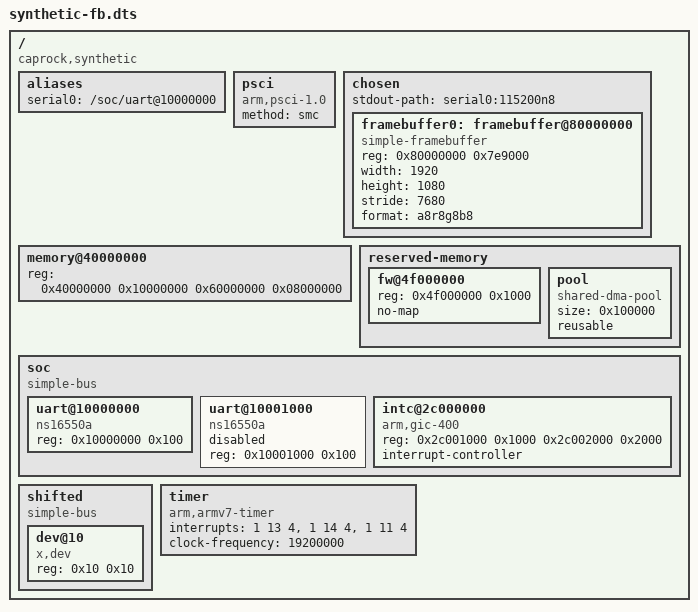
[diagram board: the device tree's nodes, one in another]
/dts-v1/;
/memreserve/ 0x4e000000 0x100000;
/* Hand-written fixture: 32-bit cells, two memory regions, header reservation, simple-framebuffer,
   alias-based stdout-path with options. Regenerate with `dtc -I dts -O dtb`. */
/ {
	#address-cells = <1>;
	#size-cells = <1>;
	compatible = "caprock,synthetic";
	aliases { serial0 = "/soc/uart@10000000"; };
	psci {
		compatible = "arm,psci-1.0", "arm,psci-0.2", "arm,psci";
		method = "smc";
	};
	chosen {
		#address-cells = <1>; #size-cells = <1>; ranges;
		stdout-path = "serial0:115200n8";
		framebuffer0: framebuffer@80000000 {
			compatible = "simple-framebuffer";
			reg = <0x80000000 0x7e9000>;
			width = <1920>;
			height = <1080>;
			stride = <7680>;
			format = "a8r8g8b8";
		};
	};
	memory@40000000 { device_type = "memory"; reg = <0x40000000 0x10000000 0x60000000 0x08000000>; };
	reserved-memory {
		#address-cells = <1>; #size-cells = <1>; ranges;
		fw@4f000000 { reg = <0x4f000000 0x1000>; no-map; };
		pool { size = <0x100000>; compatible = "shared-dma-pool"; reusable; };
	};
	soc {
		compatible = "simple-bus";
		#address-cells = <1>; #size-cells = <1>;
		ranges;
		uart@10000000 { compatible = "ns16550a"; reg = <0x10000000 0x100>; };
		uart@10001000 { compatible = "ns16550a"; reg = <0x10001000 0x100>; status = "disabled"; };
		intc@2c000000 {
			compatible = "arm,gic-400";
			reg = <0x2c001000 0x1000 0x2c002000 0x2000>;
			interrupt-controller; #interrupt-cells = <3>;
		};
	};
	shifted {
		compatible = "simple-bus";
		#address-cells = <1>; #size-cells = <1>;
		ranges = <0 0xa0000000 0x1000>;
		dev@10 { compatible = "x,dev"; reg = <0x10 0x10>; };
	};
	timer {
		compatible = "arm,armv7-timer";
		interrupts = <1 13 4>, <1 14 4>, <1 11 4>;
		clock-frequency = <19200000>;
	};
};
